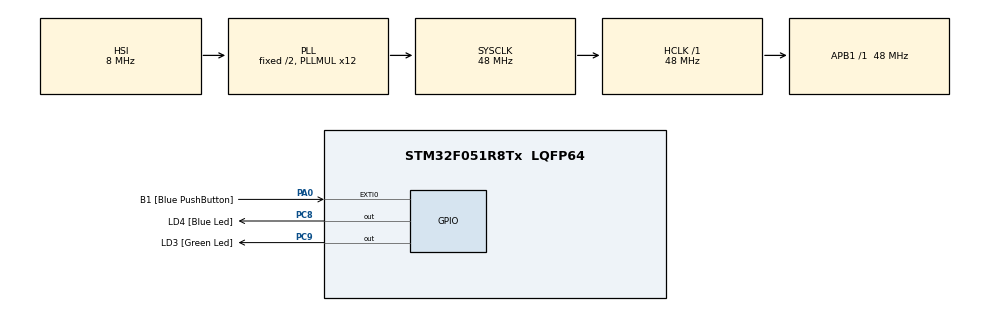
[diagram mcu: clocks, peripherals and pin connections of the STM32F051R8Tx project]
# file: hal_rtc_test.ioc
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Mcu.Family=STM32F0
Mcu.Name=STM32F051R8Tx
Mcu.Package=LQFP64
PA0.GPIO_Label=B1 [Blue PushButton]
PA0.GPIO_ModeDefaultEXTI=GPIO_MODE_EVT_RISING
PA0.Signal=GPXTI0
PA13.GPIO_Label=SWDIO
PA13.Mode=Serial_Wire
PA13.Signal=SYS_SWDIO
PA14.GPIO_Label=SWCLK
PA14.Mode=Serial_Wire
PA14.Signal=SYS_SWCLK
PC8.GPIO_Label=LD4 [Blue Led]
PC8.Signal=GPIO_Output
PC9.GPIO_Label=LD3 [Green Led]
PC9.Signal=GPIO_Output
ProjectManager.HeapSize=0x200
ProjectManager.StackSize=0x400
ProjectManager.TargetToolchain=SW4STM32
RCC.AHBFreq_Value=48000000
RCC.APB1Freq_Value=48000000
RCC.APB1TimFreq_Value=48000000
RCC.HCLKFreq_Value=48000000
RCC.PLLMUL=RCC_PLL_MUL12
RCC.SYSCLKFreq_VALUE=48000000
RCC.SYSCLKSource=RCC_SYSCLKSOURCE_PLLCLK
VP_ADC_TempSens_Input.Mode=IN-TempSens
VP_ADC_Vbat_Input.Mode=IN-Vbat
VP_ADC_Vref_Input.Mode=IN-Vrefint
VP_RTC_VS_RTC_Alarm_A_Intern.Mode=Alarm A
VP_TIM6_VS_ClockSourceINT.Mode=Enable_Timer
board=STM32F0DISCOVERY

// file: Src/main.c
/**
  ******************************************************************************
  * File Name          : main.c
  * Description        : Main program body
  ******************************************************************************
  *
  * COPYRIGHT(c) 2016 STMicroelectronics
  *
  * Redistribution and use in source and binary forms, with or without modification,
  * are permitted provided that the following conditions are met:
  *   1. Redistributions of source code must retain the above copyright notice,
  *      this list of conditions and the following disclaimer.
  *   2. Redistributions in binary form must reproduce the above copyright notice,
  *      this list of conditions and the following disclaimer in the documentation
  *      and/or other materials provided with the distribution.
  *   3. Neither the name of STMicroelectronics nor the names of its contributors
  *      may be used to endorse or promote products derived from this software
  *      without specific prior written permission.
  *
  * THIS SOFTWARE IS PROVIDED BY THE COPYRIGHT HOLDERS AND CONTRIBUTORS "AS IS"
  * AND ANY EXPRESS OR IMPLIED WARRANTIES, INCLUDING, BUT NOT LIMITED TO, THE
  * IMPLIED WARRANTIES OF MERCHANTABILITY AND FITNESS FOR A PARTICULAR PURPOSE ARE
  * DISCLAIMED. IN NO EVENT SHALL THE COPYRIGHT HOLDER OR CONTRIBUTORS BE LIABLE
  * FOR ANY DIRECT, INDIRECT, INCIDENTAL, SPECIAL, EXEMPLARY, OR CONSEQUENTIAL
  * DAMAGES (INCLUDING, BUT NOT LIMITED TO, PROCUREMENT OF SUBSTITUTE GOODS OR
  * SERVICES; LOSS OF USE, DATA, OR PROFITS; OR BUSINESS INTERRUPTION) HOWEVER
  * CAUSED AND ON ANY THEORY OF LIABILITY, WHETHER IN CONTRACT, STRICT LIABILITY,
  * OR TORT (INCLUDING NEGLIGENCE OR OTHERWISE) ARISING IN ANY WAY OUT OF THE USE
  * OF THIS SOFTWARE, EVEN IF ADVISED OF THE POSSIBILITY OF SUCH DAMAGE.
  *
  ******************************************************************************
  */
#include "stm32f0xx_hal.h"
#include "adc.h"
#include "rtc.h"
#include "tim.h"
#include "gpio.h"

/* USER CODE BEGIN Includes */
#include "stm32f0308_discovery.h"

/* USER CODE END Includes */

/* USER CODE BEGIN PV */
/* Private variables ---------------------------------------------------------*/
/* RTC handler declaration */
RTC_HandleTypeDef RtcHandle;

/* Buffer used for displaying Time */
uint8_t aShowTime[50] = {0};

/* USER CODE END PV */

void SystemClock_Config(void);
void Error_Handler(void);

/* USER CODE BEGIN PFP */
/* Private function prototypes -----------------------------------------------*/
static void RTC_AlarmConfig(void);
static void RTC_TimeShow(uint8_t* showtime);

/* USER CODE END PFP */

int main(void)
{

  /* MCU Configuration----------------------------------------------------------*/

  /* Reset of all peripherals, Initializes the Flash interface and the Systick. */
  HAL_Init();

  /* Configure the system clock */
  SystemClock_Config();

  /* Initialize all configured peripherals */
  MX_GPIO_Init();
  MX_ADC_Init();
  MX_RTC_Init();
  MX_TIM6_Init();

  /* USER CODE BEGIN 2 */
  RtcHandle = get_Rtc_Handle();

  /*##-1- set RTC time #######################################*/

  if (RTC_Set_Time(0x23, 0x58, 0x00) != HAL_OK)
  {
	  Error_Handler();
  }

  /* Configure RTC Alarm */
//  if (RTC_AlarmConfig() != HAL_OK)
//  {
//	  Error_Handler();
//  }
  RTC_AlarmConfig();

  /* USER CODE END 2 */

  /* Infinite loop */
  /* USER CODE BEGIN WHILE */
  while (1)
  {
	BSP_LED_Toggle(LED_GREEN);
	RTC_TimeShow(aShowTime);
	HAL_Delay(1000);

  /* USER CODE END WHILE */

  }

}

/** System Clock Configuration
*/
void SystemClock_Config(void)
{

  RCC_OscInitTypeDef RCC_OscInitStruct;
  RCC_ClkInitTypeDef RCC_ClkInitStruct;
  RCC_PeriphCLKInitTypeDef PeriphClkInit;

  RCC_OscInitStruct.OscillatorType = RCC_OSCILLATORTYPE_HSI|RCC_OSCILLATORTYPE_HSI14
                              |RCC_OSCILLATORTYPE_LSI;
  RCC_OscInitStruct.HSIState = RCC_HSI_ON;
  RCC_OscInitStruct.HSI14State = RCC_HSI14_ON;
  RCC_OscInitStruct.HSICalibrationValue = 16;
  RCC_OscInitStruct.HSI14CalibrationValue = 16;
  RCC_OscInitStruct.LSIState = RCC_LSI_ON;
  RCC_OscInitStruct.PLL.PLLState = RCC_PLL_ON;
  RCC_OscInitStruct.PLL.PLLSource = RCC_PLLSOURCE_HSI;
  RCC_OscInitStruct.PLL.PLLMUL = RCC_PLL_MUL12;
  RCC_OscInitStruct.PLL.PREDIV = RCC_PREDIV_DIV1;
  if (HAL_RCC_OscConfig(&RCC_OscInitStruct) != HAL_OK)
  {
    Error_Handler();
  }

  RCC_ClkInitStruct.ClockType = RCC_CLOCKTYPE_HCLK|RCC_CLOCKTYPE_SYSCLK
                              |RCC_CLOCKTYPE_PCLK1;
  RCC_ClkInitStruct.SYSCLKSource = RCC_SYSCLKSOURCE_PLLCLK;
  RCC_ClkInitStruct.AHBCLKDivider = RCC_SYSCLK_DIV1;
  RCC_ClkInitStruct.APB1CLKDivider = RCC_HCLK_DIV1;
  if (HAL_RCC_ClockConfig(&RCC_ClkInitStruct, FLASH_LATENCY_1) != HAL_OK)
  {
    Error_Handler();
  }

  PeriphClkInit.PeriphClockSelection = RCC_PERIPHCLK_RTC;
  PeriphClkInit.RTCClockSelection = RCC_RTCCLKSOURCE_LSI;
  if (HAL_RCCEx_PeriphCLKConfig(&PeriphClkInit) != HAL_OK)
  {
    Error_Handler();
  }

  HAL_SYSTICK_Config(HAL_RCC_GetHCLKFreq()/1000);

  HAL_SYSTICK_CLKSourceConfig(SYSTICK_CLKSOURCE_HCLK);

  /* SysTick_IRQn interrupt configuration */
  HAL_NVIC_SetPriority(SysTick_IRQn, 0, 0);
}

/* USER CODE BEGIN 4 */

/**
  * @brief  Alarm callback
  * @param  hrtc : RTC handle
  * @retval None
  */
void HAL_RTC_AlarmAEventCallback(RTC_HandleTypeDef *hrtc)
{
  /* Turn LED3 on: Alarm generation */
  BSP_LED_On(LED_BLUE);
}

/**
  * @brief  Configure the current time and date.
  * @param  None
  * @retval None
  */
static void RTC_AlarmConfig(void)
{
	  RTC_DateTypeDef  sdatestructure;
	  RTC_TimeTypeDef  stimestructure;
	  RTC_AlarmTypeDef salarmstructure;

	  /*##-1- Configure the Date #################################################*/
	  /* Set Date: Tuesday February 18th 2014 */
	  sdatestructure.Year = 0x14;
	  sdatestructure.Month = RTC_MONTH_FEBRUARY;
	  sdatestructure.Date = 0x18;
	  sdatestructure.WeekDay = RTC_WEEKDAY_TUESDAY;

	  if(HAL_RTC_SetDate(&RtcHandle,&sdatestructure,RTC_FORMAT_BCD) != HAL_OK)
	  {
			/* Initialization Error */
			Error_Handler();
	  }

	  /*##-2- Configure the Time #################################################*/
	  /* Set Time: 02:20:00 */
	  stimestructure.Hours = 0x02;
	  stimestructure.Minutes = 0x20;
	  stimestructure.Seconds = 0x00;
	  stimestructure.TimeFormat = RTC_HOURFORMAT12_AM;
	  stimestructure.DayLightSaving = RTC_DAYLIGHTSAVING_NONE ;
	  stimestructure.StoreOperation = RTC_STOREOPERATION_RESET;

	  if(HAL_RTC_SetTime(&RtcHandle,&stimestructure,RTC_FORMAT_BCD) != HAL_OK)
	  {
			/* Initialization Error */
			Error_Handler();
	  }

	  /*##-3- Configure the RTC Alarm peripheral #################################*/
	  /* Set Alarm to 02:20:30
		 RTC Alarm Generation: Alarm on Hours, Minutes and Seconds */
	  salarmstructure.Alarm = RTC_ALARM_A;
	  salarmstructure.AlarmDateWeekDay = RTC_WEEKDAY_MONDAY;
	  salarmstructure.AlarmDateWeekDaySel = RTC_ALARMDATEWEEKDAYSEL_DATE;
	  salarmstructure.AlarmMask = RTC_ALARMMASK_DATEWEEKDAY;
	  salarmstructure.AlarmSubSecondMask = RTC_ALARMSUBSECONDMASK_NONE;
	  salarmstructure.AlarmTime.TimeFormat = RTC_HOURFORMAT12_AM;
	  salarmstructure.AlarmTime.Hours = 0x02;
	  salarmstructure.AlarmTime.Minutes = 0x20;
	  salarmstructure.AlarmTime.Seconds = 0x30;
	  salarmstructure.AlarmTime.SubSeconds = 0x56;

	  if(HAL_RTC_SetAlarm_IT(&RtcHandle,&salarmstructure,RTC_FORMAT_BCD) != HAL_OK)
	  {
			/* Initialization Error */
			Error_Handler();
	  }
}

/**
  * @brief  Display the current time.
  * @param  showtime : pointer to buffer
  * @retval None
  */
static void RTC_TimeShow(uint8_t* showtime)
{
  RTC_DateTypeDef sdatestructureget;
  RTC_TimeTypeDef stimestructureget;

  /* Get the RTC current Time */
  HAL_RTC_GetTime(&RtcHandle, &stimestructureget, RTC_FORMAT_BIN);
  /* Get the RTC current Date */
  HAL_RTC_GetDate(&RtcHandle, &sdatestructureget, RTC_FORMAT_BIN);
  /* Display time Format : hh:mm:ss */
  sprintf((char*)showtime,"%02d:%02d:%02d",stimestructureget.Hours, stimestructureget.Minutes, stimestructureget.Seconds);
}

/* USER CODE END 4 */

void Error_Handler(void)
{
  /* USER CODE BEGIN Error_Handler */
  /* User can add his own implementation to report the HAL error return state */
  while(1)
  {
		BSP_LED_Toggle(LED_BLUE);
		HAL_Delay(200);
  }
  /* USER CODE END Error_Handler */
}

/************************ (C) COPYRIGHT STMicroelectronics *****END OF FILE****/
